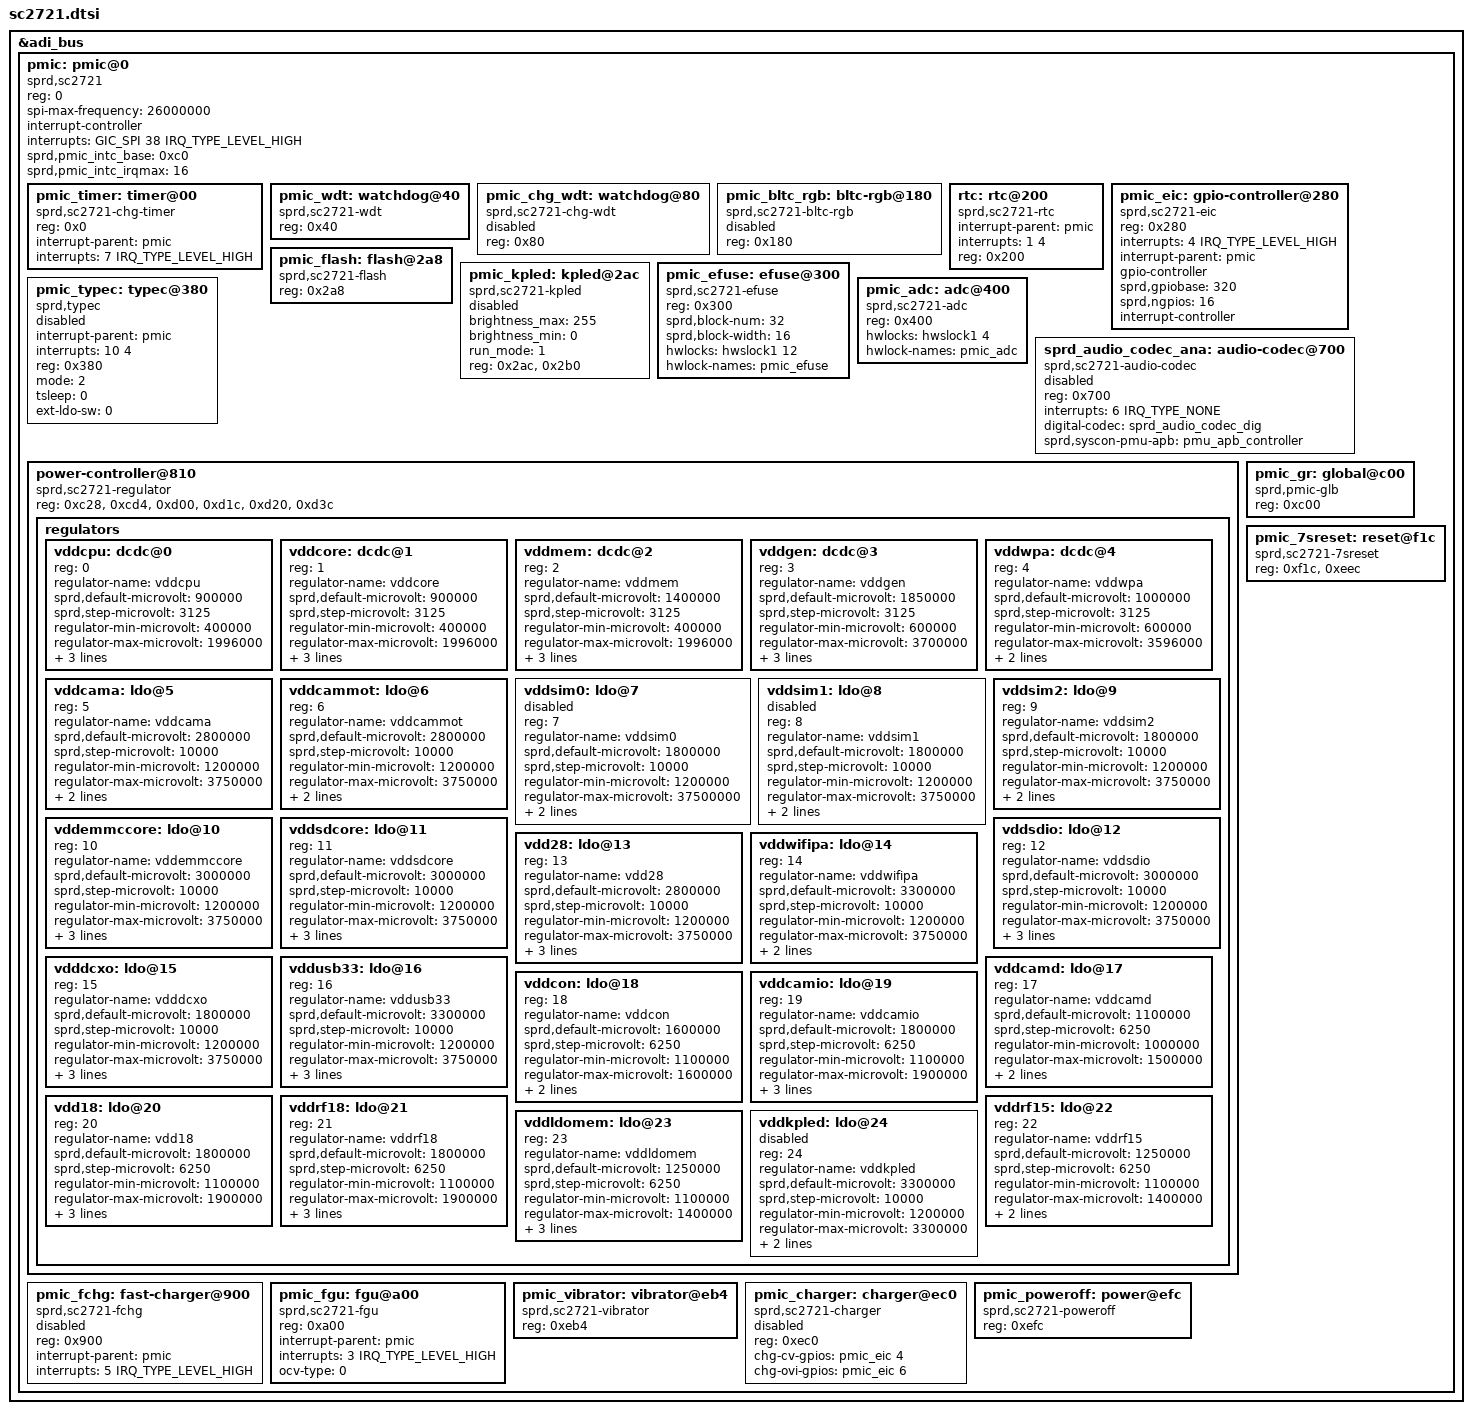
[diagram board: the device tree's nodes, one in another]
/*
 * Spreadtrum Analog Die SC2721 DTS file
 *
 * Copyright (C) 2016, Spreadtrum Communications Inc.
 *
 * This file is licensed under a dual GPLv2 or X11 license.
 */

&adi_bus {
	pmic: pmic@0 {
		compatible = "sprd,sc2721";
		reg = <0>; /* chip select 0 */
		spi-max-frequency = <26000000>;
		#address-cells = <1>;
		#size-cells = <0>;
		interrupt-controller;
		#interrupt-cells = <2>;
		interrupts = <GIC_SPI 38 IRQ_TYPE_LEVEL_HIGH>;
		sprd,pmic_intc_base = <0xc0>;
		sprd,pmic_intc_irqmax = <16>;

		pmic_timer: timer@00 {
			compatible = "sprd,sc2721-chg-timer";
			reg = <0x0>;
			interrupt-parent = <&pmic>;
			interrupts = <7 IRQ_TYPE_LEVEL_HIGH>;
		};

		pmic_wdt: watchdog@40 {
			compatible = "sprd,sc2721-wdt";
			reg = <0x40>;
		};

		pmic_chg_wdt: watchdog@80 {
			compatible = "sprd,sc2721-chg-wdt";
			reg = <0x80>;
			status = "disabled";
		};

		pmic_bltc_rgb: bltc-rgb@180 {
		       compatible = "sprd,sc2721-bltc-rgb";
		       reg = <0x180>;
		       status = "disabled";
	       };

		rtc: rtc@200 {
			compatible = "sprd,sc2721-rtc";
			interrupt-parent = <&pmic>;
			interrupts = <1 4>;
			reg = <0x200>;
		};

		pmic_eic: gpio-controller@280 {
			compatible = "sprd,sc2721-eic";
			reg = <0x280>;
			interrupts = <4 IRQ_TYPE_LEVEL_HIGH>;
			interrupt-parent = <&pmic>;
			gpio-controller;
			#gpio-cells = <2>;
			sprd,gpiobase = <320>;
			sprd,ngpios = <16>;
			interrupt-controller;
			#interrupt-cells = <2>;
		};

		pmic_flash: flash@2a8 {
			compatible = "sprd,sc2721-flash";
			reg = <0x2a8>;
		};

		pmic_kpled: kpled@2ac {
			compatible = "sprd,sc2721-kpled";
			brightness_max = <255>;
			brightness_min = <0>;
			run_mode = <1>; /* default current mode */
			reg = <0x2ac>,<0x2b0>;
			status = "disabled";
		};

		pmic_efuse: efuse@300 {
			compatible = "sprd,sc2721-efuse";
			reg = <0x300>;
			sprd,block-num = <32>;
			sprd,block-width = <16>;
			hwlocks = <&hwslock1 12>;
			hwlock-names = "pmic_efuse";
		};

		pmic_typec: typec@380 {
			compatible = "sprd,typec";
			interrupt-parent = <&pmic>;
			interrupts = <10 4>;
			reg = <0x380>;
			mode = <2>;
			tsleep = <0>;
			ext-ldo-sw = <0>;
			status = "disabled";
		};

		pmic_adc: adc@400{
			compatible = "sprd,sc2721-adc";
			reg = <0x400>;
			#io-channel-cells = <1>;
			hwlocks = <&hwslock1 4>;
			hwlock-names = "pmic_adc";
		 };

		sprd_audio_codec_ana: audio-codec@700 {
			compatible = "sprd,sc2721-audio-codec";
			#sound-dai-cells = <1>;
			reg = <0x700>;
			interrupts = <6 IRQ_TYPE_NONE>;
			digital-codec = <&sprd_audio_codec_dig>;
			sprd,syscon-pmu-apb = <&pmu_apb_controller>;
			status = "disabled";
		};

		power-controller@810 {
			compatible = "sprd,sc2721-regulator";
			reg = <0xc28>,<0xcd4>,<0xd00>,<0xd1c>,<0xd20>,<0xd3c>;

			regulators {
				#address-cells = <1>;
				#size-cells = <0>;

				vddcpu: dcdc@0 {
					reg = <0>;
					regulator-name = "vddcpu";
					sprd,default-microvolt = <900000>;
					sprd,step-microvolt = <3125>;
					regulator-min-microvolt = <400000>;
					regulator-max-microvolt = <1996000>;
					regulator-microvolt-offset = <0>;
					sprd,hide-offset = <1000>;
					sprd,default-on;
				};

				vddcore: dcdc@1 {
					reg = <1>;
					regulator-name = "vddcore";
					sprd,default-microvolt = <900000>;
					sprd,step-microvolt = <3125>;
					regulator-min-microvolt = <400000>;
					regulator-max-microvolt = <1996000>;
					regulator-microvolt-offset = <0>;
					sprd,hide-offset = <1000>;
					sprd,default-on;
				};

				vddmem: dcdc@2 {
					reg = <2>;
					regulator-name = "vddmem";
					sprd,default-microvolt = <1400000>;
					sprd,step-microvolt = <3125>;
					regulator-min-microvolt = <400000>;
					regulator-max-microvolt = <1996000>;
					regulator-microvolt-offset = <0>;
					sprd,hide-offset = <1000>;
					sprd,default-on;
				};

				vddgen: dcdc@3 {
					reg = <3>;
					regulator-name = "vddgen";
					sprd,default-microvolt = <1850000>;
					sprd,step-microvolt = <3125>;
					regulator-min-microvolt = <600000>;
					regulator-max-microvolt = <3700000>;
					regulator-microvolt-offset = <0>;
					sprd,hide-offset = <1000>;
					sprd,default-on;
				};

				vddwpa: dcdc@4 {
					reg = <4>;
					regulator-name = "vddwpa";
					sprd,default-microvolt = <1000000>;
					sprd,step-microvolt = <3125>;
					regulator-min-microvolt = <600000>;
					regulator-max-microvolt = <3596000>;
					regulator-microvolt-offset = <0>;
					sprd,hide-offset = <1000>;
				};

				vddcama: ldo@5 {
					reg = <5>;
					regulator-name = "vddcama";
					sprd,default-microvolt = <2800000>;
					sprd,step-microvolt = <10000>;
					regulator-min-microvolt = <1200000>;
					regulator-max-microvolt = <3750000>;
					regulator-microvolt-offset = <0>;
					sprd,hide-offset = <1000>;
				};

				vddcammot: ldo@6 {
					reg = <6>;
					regulator-name = "vddcammot";
					sprd,default-microvolt = <2800000>;
					sprd,step-microvolt = <10000>;
					regulator-min-microvolt = <1200000>;
					regulator-max-microvolt = <3750000>;
					regulator-microvolt-offset = <0>;
					sprd,hide-offset = <1000>;
				};

				vddsim0: ldo@7 {
					reg = <7>;
					regulator-name = "vddsim0";
					sprd,default-microvolt = <1800000>;
					sprd,step-microvolt = <10000>;
					regulator-min-microvolt = <1200000>;
					regulator-max-microvolt = <37500000>;
					regulator-microvolt-offset = <0>;
					sprd,hide-offset = <1000>;
					status = "disabled";
				};

				vddsim1: ldo@8 {
					reg = <8>;
					regulator-name = "vddsim1";
					sprd,default-microvolt = <1800000>;
					sprd,step-microvolt = <10000>;
					regulator-min-microvolt = <1200000>;
					regulator-max-microvolt = <3750000>;
					regulator-microvolt-offset = <0>;
					sprd,hide-offset = <1000>;
					status = "disabled";
				};

				vddsim2: ldo@9 {
					reg = <9>;
					regulator-name = "vddsim2";
					sprd,default-microvolt = <1800000>;
					sprd,step-microvolt = <10000>;
					regulator-min-microvolt = <1200000>;
					regulator-max-microvolt = <3750000>;
					regulator-microvolt-offset = <0>;
					sprd,hide-offset = <1000>;
				};

				vddemmccore: ldo@10 {
					reg = <10>;
					regulator-name = "vddemmccore";
					sprd,default-microvolt = <3000000>;
					sprd,step-microvolt = <10000>;
					regulator-min-microvolt = <1200000>;
					regulator-max-microvolt = <3750000>;
					regulator-microvolt-offset = <0>;
					sprd,default-on;
					sprd,hide-offset = <1000>;
				};

				vddsdcore: ldo@11 {
					reg = <11>;
					regulator-name = "vddsdcore";
					sprd,default-microvolt = <3000000>;
					sprd,step-microvolt = <10000>;
					regulator-min-microvolt = <1200000>;
					regulator-max-microvolt = <3750000>;
					regulator-microvolt-offset = <0>;
					sprd,default-on;
					sprd,hide-offset = <1000>;
				};

				vddsdio: ldo@12 {
					reg = <12>;
					regulator-name = "vddsdio";
					sprd,default-microvolt = <3000000>;
					sprd,step-microvolt = <10000>;
					regulator-min-microvolt = <1200000>;
					regulator-max-microvolt = <3750000>;
					regulator-microvolt-offset = <0>;
					sprd,default-on;
					sprd,hide-offset = <1000>;
				};

				vdd28: ldo@13 {
					reg = <13>;
					regulator-name = "vdd28";
					sprd,default-microvolt = <2800000>;
					sprd,step-microvolt = <10000>;
					regulator-min-microvolt = <1200000>;
					regulator-max-microvolt = <3750000>;
					regulator-microvolt-offset = <0>;
					sprd,default-on;
					sprd,hide-offset = <1000>;
				};

				vddwifipa: ldo@14 {
					reg = <14>;
					regulator-name = "vddwifipa";
					sprd,default-microvolt = <3300000>;
					sprd,step-microvolt = <10000>;
					regulator-min-microvolt = <1200000>;
					regulator-max-microvolt = <3750000>;
					regulator-microvolt-offset = <0>;
					sprd,hide-offset = <1000>;
				};

				vdddcxo: ldo@15 {
					reg = <15>;
					regulator-name = "vdddcxo";
					sprd,default-microvolt = <1800000>;
					sprd,step-microvolt = <10000>;
					regulator-min-microvolt = <1200000>;
					regulator-max-microvolt = <3750000>;
					regulator-microvolt-offset = <0>;
					sprd,default-on;
					sprd,hide-offset = <1000>;
				};

				vddusb33: ldo@16 {
					reg = <16>;
					regulator-name = "vddusb33";
					sprd,default-microvolt = <3300000>;
					sprd,step-microvolt = <10000>;
					regulator-min-microvolt = <1200000>;
					regulator-max-microvolt = <3750000>;
					regulator-microvolt-offset = <0>;
					sprd,default-on;
					sprd,hide-offset = <1000>;
				};

				vddcamd: ldo@17 {
					reg = <17>;
					regulator-name = "vddcamd";
					sprd,default-microvolt = <1100000>;
					sprd,step-microvolt = <6250>;
					regulator-min-microvolt = <1000000>;
					regulator-max-microvolt = <1500000>;
					regulator-microvolt-offset = <0>;
					sprd,hide-offset = <1000>;
				};

				vddcon: ldo@18 {
					reg = <18>;
					regulator-name = "vddcon";
					sprd,default-microvolt = <1600000>;
					sprd,step-microvolt = <6250>;
					regulator-min-microvolt = <1100000>;
					regulator-max-microvolt = <1600000>;
					regulator-microvolt-offset = <0>;
					sprd,hide-offset = <1000>;
				};

				vddcamio: ldo@19 {
					reg = <19>;
					regulator-name = "vddcamio";
					sprd,default-microvolt = <1800000>;
					sprd,step-microvolt = <6250>;
					regulator-min-microvolt = <1100000>;
					regulator-max-microvolt = <1900000>;
					regulator-microvolt-offset = <0>;
					sprd,hide-offset = <1000>;
					sprd,default-on;
				};

				vdd18: ldo@20 {
					reg = <20>;
					regulator-name = "vdd18";
					sprd,default-microvolt = <1800000>;
					sprd,step-microvolt = <6250>;
					regulator-min-microvolt = <1100000>;
					regulator-max-microvolt = <1900000>;
					regulator-microvolt-offset = <0>;
					sprd,hide-offset = <1000>;
					sprd,default-on;
				};

				vddrf18: ldo@21 {
					reg = <21>;
					regulator-name = "vddrf18";
					sprd,default-microvolt = <1800000>;
					sprd,step-microvolt = <6250>;
					regulator-min-microvolt = <1100000>;
					regulator-max-microvolt = <1900000>;
					regulator-microvolt-offset = <0>;
					sprd,default-on;
					sprd,hide-offset = <1000>;
				};

				vddrf15: ldo@22 {
					reg = <22>;
					regulator-name = "vddrf15";
					sprd,default-microvolt = <1250000>;
					sprd,step-microvolt = <6250>;
					regulator-min-microvolt = <1100000>;
					regulator-max-microvolt = <1400000>;
					regulator-microvolt-offset = <0>;
					sprd,hide-offset = <1000>;
				};

				vddldomem: ldo@23 {
					reg = <23>;
					regulator-name = "vddldomem";
					sprd,default-microvolt = <1250000>;
					sprd,step-microvolt = <6250>;
					regulator-min-microvolt = <1100000>;
					regulator-max-microvolt = <1400000>;
					regulator-microvolt-offset = <0>;
					sprd,hide-offset = <1000>;
					sprd,default-on;
				};

				vddkpled: ldo@24 {
					reg = <24>;
					regulator-name = "vddkpled";
					sprd,default-microvolt = <3300000>;
					sprd,step-microvolt = <10000>;
					regulator-min-microvolt = <1200000>;
					regulator-max-microvolt = <3300000>;
					regulator-microvolt-offset = <0>;
					sprd,hide-offset = <1000>;
					status = "disabled";
				};

			};
		};

		pmic_fchg: fast-charger@900 {
			compatible = "sprd,sc2721-fchg";
			reg = <0x900>;
			interrupt-parent = <&pmic>;
			interrupts = <5 IRQ_TYPE_LEVEL_HIGH>;
			status = "disabled";
		};

		pmic_fgu: fgu@a00 {
			compatible = "sprd,sc2721-fgu";
			reg = <0xa00>;
			interrupt-parent = <&pmic>;
			interrupts = <3 IRQ_TYPE_LEVEL_HIGH>;
			ocv-type = <0>;
		};

		pmic_gr: global@c00 {
			compatible = "sprd,pmic-glb";
			reg = <0xc00>;
		};

		pmic_vibrator: vibrator@eb4 {
			compatible = "sprd,sc2721-vibrator";
			reg = <0xeb4>;
		};

		pmic_charger: charger@ec0 {
			compatible = "sprd,sc2721-charger";
			reg = <0xec0>;
			chg-cv-gpios = <&pmic_eic 4 0>;
			chg-ovi-gpios = <&pmic_eic 6 0>;
			status = "disabled";
		};

		pmic_poweroff: power@efc {
			compatible = "sprd,sc2721-poweroff";
			reg = <0xefc>;
		};

		pmic_7sreset: reset@f1c {
			compatible = "sprd,sc2721-7sreset";
			reg = <0xf1c>,<0xeec>;
		};
	};
};
